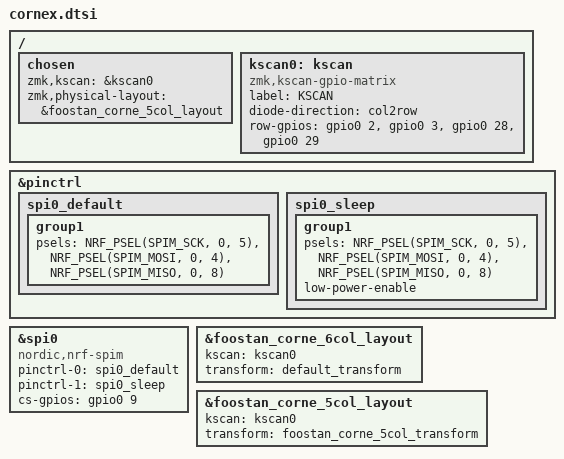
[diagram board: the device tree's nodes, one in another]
/*
 * Copyright (c) 2020 Pete Johanson
 *
 * SPDX-License-Identifier: MIT
 */

#include <dt-bindings/zmk/matrix_transform.h>
#include <layouts/foostan/corne/5column.dtsi>
#include <layouts/foostan/corne/6column.dtsi>

/ {
	chosen {
		zmk,kscan = &kscan0;
		zmk,physical-layout = &foostan_corne_5col_layout;
	};

	kscan0: kscan {
		compatible = "zmk,kscan-gpio-matrix";
		label = "KSCAN";

		diode-direction = "col2row";
		row-gpios
			= <&gpio0 2 (GPIO_ACTIVE_HIGH | GPIO_PULL_DOWN)>     //Row0
			, <&gpio0 3 (GPIO_ACTIVE_HIGH | GPIO_PULL_DOWN)>     //Row1
			, <&gpio0 28 (GPIO_ACTIVE_HIGH | GPIO_PULL_DOWN)>    //Row2
			, <&gpio0 29 (GPIO_ACTIVE_HIGH | GPIO_PULL_DOWN)>    //Row3
			;
		
	};
};


&pinctrl {
	spi0_default: spi0_default {
		group1 {
			psels = <NRF_PSEL(SPIM_SCK, 0, 5)>,
				<NRF_PSEL(SPIM_MOSI, 0, 4)>,
				<NRF_PSEL(SPIM_MISO, 0, 8)>;
		};
	};
	spi0_sleep: spi0_sleep {
		group1 {
			psels = <NRF_PSEL(SPIM_SCK, 0, 5)>,
				<NRF_PSEL(SPIM_MOSI, 0, 4)>,
				<NRF_PSEL(SPIM_MISO, 0, 8)>;
			low-power-enable;
		};
	};	
};

nice_view_spi: &spi0 {
	compatible = "nordic,nrf-spim";
	pinctrl-0 = <&spi0_default>;
	pinctrl-1 = <&spi0_sleep>;
	pinctrl-names = "default", "sleep";
	cs-gpios = <&gpio0 9 GPIO_ACTIVE_HIGH>;
};

// Assign kscan to the predefined layouts
&foostan_corne_6col_layout {
    kscan = <&kscan0>;
    transform = <&default_transform>;
};

&foostan_corne_5col_layout {
    kscan = <&kscan0>;
    transform = <&foostan_corne_5col_transform>;
};


